# ATSAM4LS2C register map
Vendor: Atmel Corporation; Series: SAM4L; File version: B
CPU: CM4 r0p1, little endian, MPU, no FPU, 4 interrupt priority bits
Registers are 32-bit, write-only, reset 0x0 unless marked. A register's access mark holds for its fields unless they carry their own. Offsets are from the block's base; [hi:lo] are bit positions; {n}, {i} and the like mark numbered series; 'fields as' and 'values as' point back to an identical list.

## PDCA — Peripheral DMA Controller
Base 0x400A2000; register names take the prefix PDCA_
{0x0+0x40*i} MAR{i} (i=0..15) rw — Memory Address Register
  [31:0] MADDR — Memory Address
{0x4+0x40*i} PSR{i} (i=0..15) rw — Peripheral Select Register
  [7:0] PID — Peripheral Identifier
{0x8+0x40*i} TCR{i} (i=0..15) rw — Transfer Counter Register
  [15:0] TCV — Transfer Counter Value
{0xC+0x40*i} MARR{i} (i=0..15) rw — Memory Address Reload Register
  [31:0] MARV — Memory Address Reload Value
{0x10+0x40*i} TCRR{i} (i=0..15) rw — Transfer Counter Reload Register
  [15:0] TCRV — Transfer Counter Reload Value
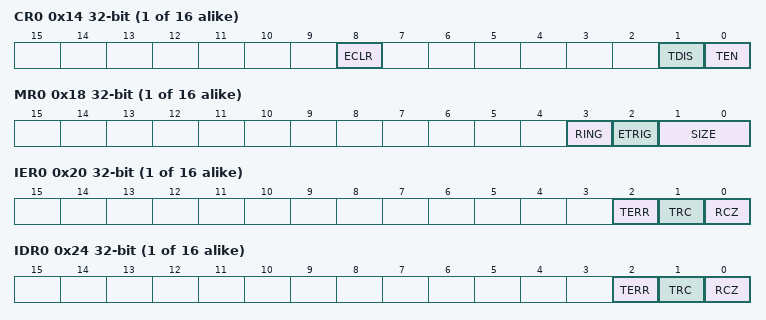
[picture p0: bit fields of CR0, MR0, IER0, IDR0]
{0x14+0x40*i} CR{i} (i=0..15) — Control Register
  [8] ECLR — Error Clear
  [1] TDIS — Transfer Disable
  [0] TEN — Transfer Enable
{0x18+0x40*i} MR{i} (i=0..15) rw — Mode Register
  [3] RING — Ring Buffer
  [2] ETRIG — Event trigger
  [1:0] SIZE — Transfer size
    0=Byte; 1=Half_Word; 2=Word
{0x1C+0x40*i} SR{i} (i=0..15) ro — Status Register
  [0] TEN — Transfer Enabled
{0x20+0x40*i} IER{i} (i=0..15) — Interrupt Enable Register
  [2] TERR — Transfer Error
  [1] TRC — Transfer Complete
  [0] RCZ — Reload Counter Zero
{0x24+0x40*i} IDR{i} (i=0..15) — Interrupt Disable Register
  fields as IER0
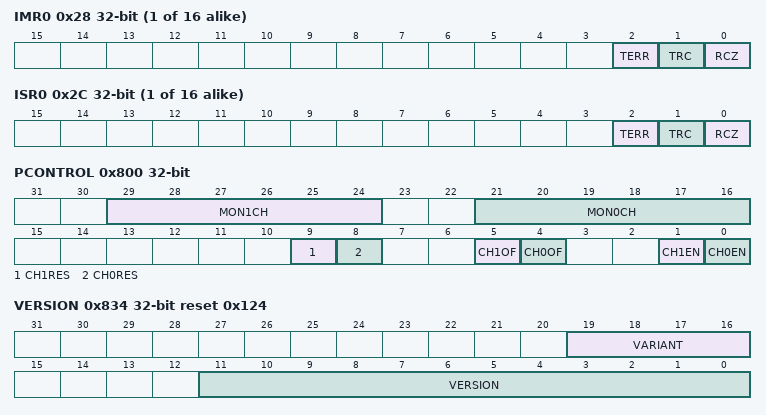
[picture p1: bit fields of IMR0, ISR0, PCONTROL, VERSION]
{0x28+0x40*i} IMR{i} (i=0..15) ro — Interrupt Mask Register
  fields as IER0
{0x2C+0x40*i} ISR{i} (i=0..15) ro — Interrupt Status Register
  fields as IER0
0x800 PCONTROL rw — Performance Control Register
  [29:24] MON1CH — PDCA Channel to monitor with counter 1
  [21:16] MON0CH — PDCA Channel to monitor with counter 0
  [9] CH1RES — Channel 1 counter reset
  [8] CH0RES — Channel 0 counter reset
  [5] CH1OF — Channel 1 overflow freeze
  [4] CH0OF — Channel 0 Overflow Freeze
  [1] CH1EN — Channel 1 Enabled.
  [0] CH0EN — Channel 0 Enabled
0x804 PRDATA0 ro — Channel 0 Read Data Cycles
  [31:0] DATA — Data Cycles Counted Since Last reset
0x808 PRSTALL0 ro — Channel 0 Read Stall Cycles
  [31:0] STALL — Stall Cycles counted since last reset
0x80C PRLAT0 ro — Channel 0 Read Max Latency
  [15:0] LAT — Maximum Transfer Initiation cycles counted since last reset
0x810 PWDATA0 ro — Channel 0 Write Data Cycles
  [31:0] DATA — Data Cycles Counted since last Reset
0x814 PWSTALL0 ro — Channel 0 Write Stall Cycles
  [31:0] STALL — Stall cycles counted since last reset
0x818 PWLAT0 ro — Channel0 Write Max Latency
  [15:0] LAT — Maximum transfer initiation cycles counted since last reset
0x81C PRDATA1 ro — Channel 1 Read Data Cycles
  [31:0] DATA — Data Cycles Counted Since Last reset
0x820 PRSTALL1 ro — Channel Read Stall Cycles
  [31:0] STALL — Stall Cycles Counted since last reset
0x824 PRLAT1 ro — Channel 1 Read Max Latency
  [15:0] LAT — Maximum Transfer initiation cycles counted since last reset
0x828 PWDATA1 ro — Channel 1 Write Data Cycles
  [31:0] DATA — Data cycles Counted Since last reset
0x82C PWSTALL1 ro — Channel 1 Write stall Cycles
  [31:0] STALL — Stall cycles counted since last reset
0x830 PWLAT1 ro — Channel 1 Read Max Latency
  fields as PWLAT0
0x834 VERSION ro reset 0x124
  [19:16] VARIANT — Variant Number
  [11:0] VERSION — Version Number

## PEVC — Peripheral Event Controller
Base 0x400A6000; register names take the prefix PEVC_
0x00 CHSR ro — Channel Status Register
  [31:0] CHS — Channel Status
    0=Channel j Disabled; 1=Channel j Enabled
0x04 CHER — Channel Enable Register
  [31:0] CHE — Channel Enable
    0=No Action; 1=Enable Channel j
0x08 CHDR — Channel Disable Register
  [31:0] CHD — Channel Disable
    0=No Action; 1=Disable Channel j
0x10 SEV — Software Event
  [31:0] SEV
    0=No Action; 1=CPU forces software event to channel j
0x14 BUSY ro — Channel / User Busy
  [31:0] BUSY — Channel Status
    0=No Action; 1=Channel j or User j is Busy
0x20 TRIER — Trigger Interrupt Mask Enable Register
  [31:0] TRIE — Trigger Interrupt Enable
    0=No Action; 1=Enable Trigger j Interrupt
0x24 TRIDR — Trigger Interrupt Mask Disable Register
  [31:0] TRID — Trigger Interrupt Disable
    0=No Action; 1=Disable Trigger j Interrupt
0x28 TRIMR ro — Trigger Interrupt Mask Register
  [31:0] TRIM — Trigger Interrupt Mask
    0=Trigger j Interrupt Disabled; 1=Trigger j Interrupt Enabled
0x30 TRSR ro — Trigger Status Register
  [31:0] TRS — Trigger Interrupt Status
    0=Channel j did not send out an Event in the past; 1=Channel j did send out an Event in the past
0x34 TRSCR — Trigger Status Clear Register
  [31:0] TRSC — Trigger Interrupt Status Clear
    0=No Action; 1=Clear TRSR[j]
0x40 OVIER — Overrun Interrupt Mask Enable Register
  [31:0] OVIE — Overrun Interrupt Enable
    0=No Action; 1=Enable Overrun Interrupt for Channel j
0x44 OVIDR — Overrun Interrupt Mask Disable Register
  [31:0] OVID — Overrun Interrupt Disable
    0=No Action; 1=Enable Overrun Interrupt for Channel j
0x48 OVIMR ro — Overrun Interrupt Mask Register
  [31:0] OVIM — Overrun Interrupt Mask
    0=Overrun Interrupt for Channel j Disabled; 1=Overrun Interrupt for Channel j Enabled
0x50 OVSR ro — Overrun Status Register
  [31:0] OVS — Overrun Interrupt Status
    0=No Overrun occured on Channel j; 1=Overrun occured on Channel j
0x54 OVSCR — Overrun Status Clear Register
  [31:0] OVSC — Overrun Interrupt Status Clear
    0=No Action; 1=Clear Overrun Status Bit j
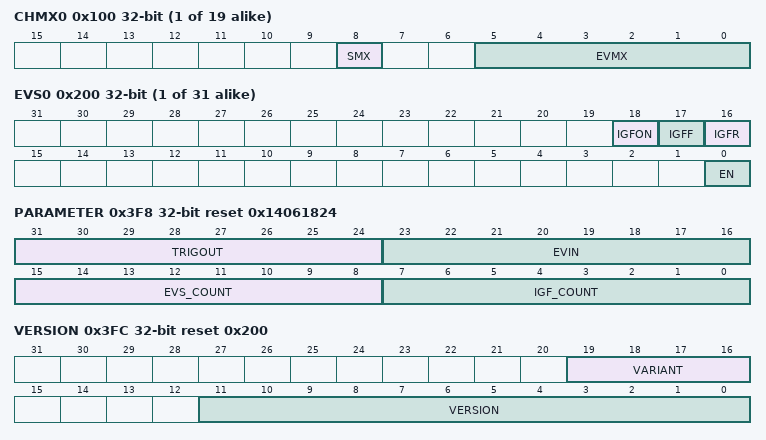
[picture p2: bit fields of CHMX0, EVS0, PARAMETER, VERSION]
{0x100+4i} CHMX{i} (i=0..18) rw — Channel Multiplexer
  [8] SMX — Software Event Multiplexer
    0=Hardware events; 1=Software event
  [5:0] EVMX — Event Multiplexer
    0=Event 0; 1=Event 1
{0x200+4i} EVS{i} (i=0..30) rw — Event Shaper
  [18] IGFON — Input Glitch Filter Status
  [17] IGFF — Input Glitch Filter Fall
    0=No Action; 1=Input Glitch Filter : a falling edge on event input will raise trigger output
  [16] IGFR — Input Glitch Filter Rise
    0=No Action; 1=Input Glitch Filter : a rising edge on event input will raise trigger output
  [0] EN — Event Shaper Enable
    0=No Action; 1=Event Shaper enable
0x300 IGFDR rw — Input Glitch Filter Divider Register
  [3:0] IGFDR
0x3F8 PARAMETER ro reset 0x14061824
  [31:24] TRIGOUT — Number of Trigger Outputs / Channels / Users
  [23:16] EVIN — Number of Event Inputs / Generators
  [15:8] EVS_COUNT — Number of Event Shapers
  [7:0] IGF_COUNT — Number of Input Glitch Filters
0x3FC VERSION ro reset 0x200
  [19:16] VARIANT — Variant Number
  [11:0] VERSION — Version Number

## Notices in the file
Atmel Microcontroller Software Support
Copyright (c) 2016 Atmel Corporation,
a wholly owned subsidiary of Microchip Technology Inc.
Licensed under the Apache License, Version 2.0 (the "License");
you may not use this file except in compliance with the License.
You may obtain a copy of the Licence at
http://www.apache.org/licenses/LICENSE-2.0
Unless required by applicable law or agreed to in writing, software
distributed under the License is distributed on an "AS IS" BASIS,
WITHOUT WARRANTIES OR CONDITIONS OF ANY KIND, either express or implied.
See the License for the specific language governing permissions and
limitations under the License.
